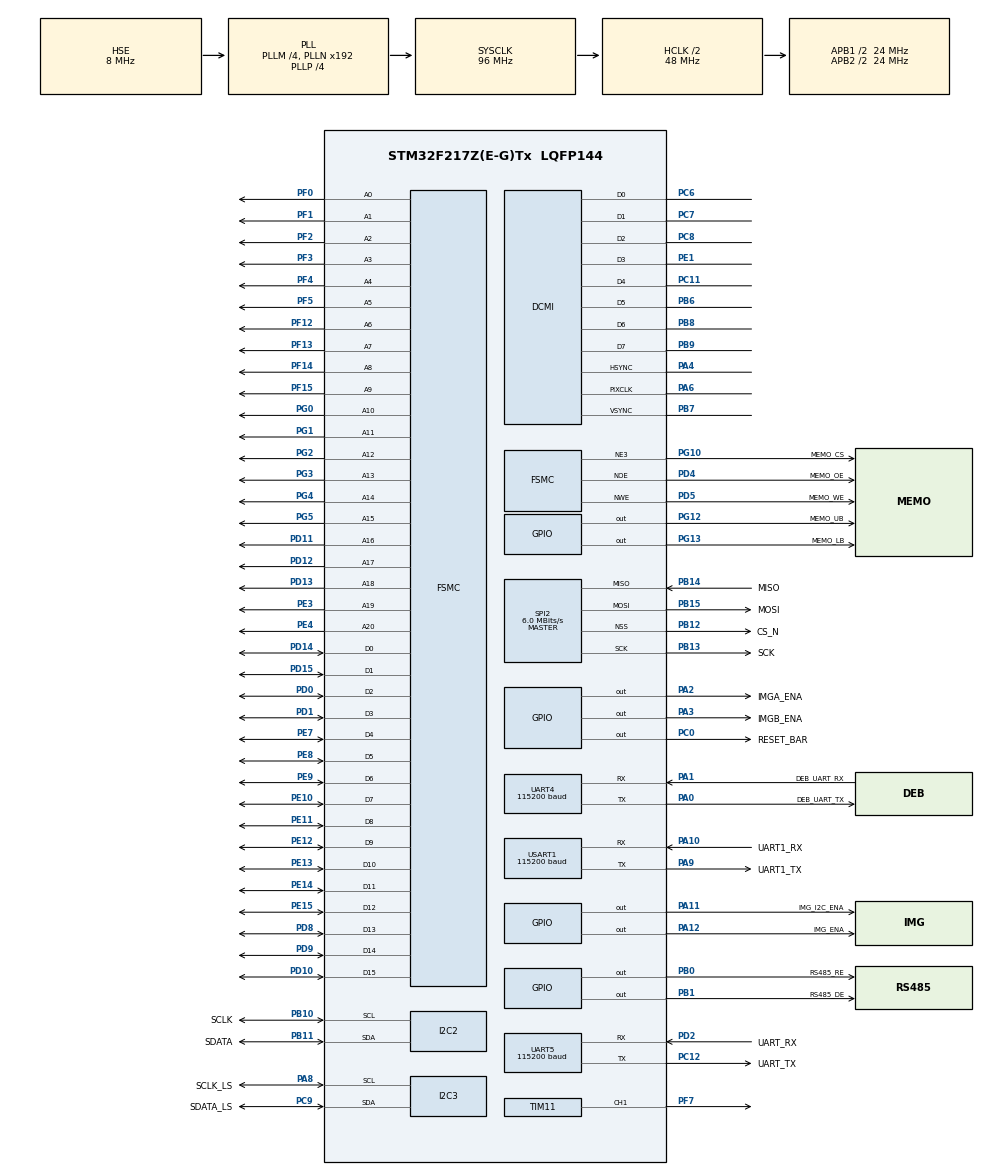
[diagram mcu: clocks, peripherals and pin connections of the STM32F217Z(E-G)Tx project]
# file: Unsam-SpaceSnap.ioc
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DCMI.HSPolarity=DCMI_HSPOLARITY_HIGH
DCMI.JPEGMode=DCMI_JPEG_DISABLE
DCMI.VSPolarity=DCMI_VSPOLARITY_HIGH
FSMC.AddressSetupTime1=2
FSMC.BusTurnAroundDuration1=2
FSMC.DataSetupTime1=2
FSMC.WriteOperation1=FSMC_WRITE_OPERATION_ENABLE
I2C2.AddressingMode=I2C_ADDRESSINGMODE_10BIT
I2C3.OwnAddress=0x7
Mcu.Family=STM32F2
Mcu.Name=STM32F217Z(E-G)Tx
Mcu.Package=LQFP144
NVIC.PriorityGroup=NVIC_PRIORITYGROUP_4
PA0-WKUP.GPIO_Label=DEB_UART_TX
PA0-WKUP.Mode=Asynchronous
PA0-WKUP.Signal=UART4_TX
PA1.GPIO_Label=DEB_UART_RX
PA1.Mode=Asynchronous
PA1.Signal=UART4_RX
PA10.GPIO_Label=UART1_RX
PA10.Mode=Asynchronous
PA10.Signal=USART1_RX
PA11.GPIO_Label=IMG_I2C_ENA
PA11.GPIO_PuPd=GPIO_NOPULL
PA11.Signal=GPIO_Output
PA12.GPIO_Label=IMG_ENA
PA12.Signal=GPIO_Output
PA13.Mode=JTAG_5_pins
PA13.Signal=SYS_JTMS-SWDIO
PA14.Mode=JTAG_5_pins
PA14.Signal=SYS_JTCK-SWCLK
PA15.Mode=JTAG_5_pins
PA15.Signal=SYS_JTDI
PA2.GPIO_Label=IMGA_ENA
PA2.Signal=GPIO_Output
PA3.GPIO_Label=IMGB_ENA
PA3.Signal=GPIO_Output
PA4.Mode=Slave_8_bits_External_Synchro
PA4.Signal=DCMI_HSYNC
PA6.Mode=Slave_8_bits_External_Synchro
PA6.Signal=DCMI_PIXCLK
PA8.GPIO_Label=SCLK_LS
PA8.Mode=I2C
PA8.Signal=I2C3_SCL
PA9.GPIO_Label=UART1_TX
PA9.Mode=Asynchronous
PA9.Signal=USART1_TX
PB0.GPIO_Label=RS485_RE
PB0.Signal=GPIO_Output
PB1.GPIO_Label=RS485_DE
PB1.Signal=GPIO_Output
PB10.GPIO_Label=SCLK
PB10.Mode=I2C
PB10.Signal=I2C2_SCL
PB11.GPIO_Label=SDATA
PB11.Mode=I2C
PB11.Signal=I2C2_SDA
PB12.GPIO_Label=CS_N
PB12.Mode=NSS_Signal_Hard_Output
PB12.Signal=SPI2_NSS
PB13.GPIO_Label=SCK
PB13.Mode=Full_Duplex_Master
PB13.Signal=SPI2_SCK
PB14.GPIO_Label=MISO
PB14.Mode=Full_Duplex_Master
PB14.Signal=SPI2_MISO
PB15.GPIO_Label=MOSI
PB15.Mode=Full_Duplex_Master
PB15.Signal=SPI2_MOSI
PB3.Mode=JTAG_5_pins
PB3.Signal=SYS_JTDO-SWO
PB4.Mode=JTAG_5_pins
PB4.Signal=SYS_JTRST
PB6.Mode=Slave_8_bits_External_Synchro
PB6.Signal=DCMI_D5
PB7.Mode=Slave_8_bits_External_Synchro
PB7.Signal=DCMI_VSYNC
PB8.Mode=Slave_8_bits_External_Synchro
PB8.Signal=DCMI_D6
PB9.Mode=Slave_8_bits_External_Synchro
PB9.Signal=DCMI_D7
PC0.GPIO_Label=RESET_BAR
PC0.Signal=GPIO_Output
PC11.Mode=Slave_8_bits_External_Synchro
PC11.Signal=DCMI_D4
PC12.GPIO_Label=UART_TX
PC12.Mode=Asynchronous
PC12.Signal=UART5_TX
PC14-OSC32_IN.Mode=LSE-External-Oscillator
PC14-OSC32_IN.Signal=RCC_OSC32_IN
PC15-OSC32_OUT.Mode=LSE-External-Oscillator
PC15-OSC32_OUT.Signal=RCC_OSC32_OUT
PC6.Mode=Slave_8_bits_External_Synchro
PC6.Signal=DCMI_D0
PC7.Mode=Slave_8_bits_External_Synchro
PC7.Signal=DCMI_D1
PC8.Mode=Slave_8_bits_External_Synchro
PC8.Signal=DCMI_D2
PC9.GPIO_Label=SDATA_LS
PC9.Mode=I2C
PC9.Signal=I2C3_SDA
PD0.Signal=FSMC_D2_DA2
PD1.Signal=FSMC_D3_DA3
PD10.Signal=FSMC_D15_DA15
PD11.Signal=FSMC_A16_CLE
PD12.Signal=FSMC_A17_ALE
PD13.Signal=FSMC_A18
PD14.Signal=FSMC_D0_DA0
PD15.Signal=FSMC_D1_DA1
PD2.GPIO_Label=UART_RX
PD2.Mode=Asynchronous
PD2.Signal=UART5_RX
PD4.GPIO_Label=MEMO_OE
PD4.Signal=FSMC_NOE
PD5.GPIO_Label=MEMO_WE
PD5.Signal=FSMC_NWE
PD8.Signal=FSMC_D13_DA13
PD9.Signal=FSMC_D14_DA14
PE1.Mode=Slave_8_bits_External_Synchro
PE1.Signal=DCMI_D3
PE10.Signal=FSMC_D7_DA7
PE11.Signal=FSMC_D8_DA8
PE12.Signal=FSMC_D9_DA9
PE13.Signal=FSMC_D10_DA10
PE14.Signal=FSMC_D11_DA11
PE15.Signal=FSMC_D12_DA12
PE3.Signal=FSMC_A19
PE4.Signal=FSMC_A20
PE7.Signal=FSMC_D4_DA4
PE8.Signal=FSMC_D5_DA5
PE9.Signal=FSMC_D6_DA6
PF0.Signal=FSMC_A0
PF1.Signal=FSMC_A1
PF12.Signal=FSMC_A6
PF13.Signal=FSMC_A7
PF14.Signal=FSMC_A8
PF15.Signal=FSMC_A9
PF2.Signal=FSMC_A2
PF3.Signal=FSMC_A3
PF4.Signal=FSMC_A4
PF5.Signal=FSMC_A5
PF7.Signal=S_TIM11_CH1
PG0.Signal=FSMC_A10
PG1.Signal=FSMC_A11
PG10.GPIO_Label=MEMO_CS
PG10.Mode=NorPsramChipSelect3_1
PG10.Signal=FSMC_NE3
PG12.GPIO_Label=MEMO_UB
PG12.GPIO_ModeDefaultOutputPP=GPIO_MODE_OUTPUT_PP
PG12.GPIO_PuPd=GPIO_PULLDOWN
PG12.Signal=GPIO_Output
PG13.GPIO_Label=MEMO_LB
PG13.GPIO_PuPd=GPIO_PULLDOWN
PG13.Signal=GPIO_Output
PG2.Signal=FSMC_A12
PG3.Signal=FSMC_A13
PG4.Signal=FSMC_A14
PG5.Signal=FSMC_A15
PH0-OSC_IN.GPIO_Label=OSC_IN
PH0-OSC_IN.Mode=HSE-External-Oscillator
PH0-OSC_IN.Signal=RCC_OSC_IN
PH1-OSC_OUT.GPIO_Label=OSC_OUT
PH1-OSC_OUT.Mode=HSE-External-Oscillator
PH1-OSC_OUT.Signal=RCC_OSC_OUT
ProjectManager.HeapSize=0x200
ProjectManager.StackSize=0x400
ProjectManager.TargetToolchain=STM32CubeIDE
RCC.48MHZClocksFreq_Value=96000000
RCC.AHBCLKDivider=RCC_SYSCLK_DIV2
RCC.AHBFreq_Value=48000000
RCC.APB1CLKDivider=RCC_HCLK_DIV2
RCC.APB1Freq_Value=24000000
RCC.APB1TimFreq_Value=48000000
RCC.APB2CLKDivider=RCC_HCLK_DIV2
RCC.APB2Freq_Value=24000000
RCC.APB2TimFreq_Value=48000000
RCC.CortexFreq_Value=48000000
RCC.HCLKFreq_Value=48000000
RCC.HSE_VALUE=8000000
RCC.HSI_VALUE=16000000
RCC.PLLM=4
RCC.PLLP=RCC_PLLP_DIV4
RCC.PLLSourceVirtual=RCC_PLLSOURCE_HSE
RCC.SYSCLKFreq_VALUE=96000000
RCC.SYSCLKSource=RCC_SYSCLKSOURCE_PLLCLK
RCC.VCOOutputFreq_Value=384000000
SH.FSMC_A0.0=FSMC_A0,21b-a1
SH.FSMC_A1.0=FSMC_A1,21b-a1
SH.FSMC_A10.0=FSMC_A10,21b-a1
SH.FSMC_A11.0=FSMC_A11,21b-a1
SH.FSMC_A12.0=FSMC_A12,21b-a1
SH.FSMC_A13.0=FSMC_A13,21b-a1
SH.FSMC_A14.0=FSMC_A14,21b-a1
SH.FSMC_A15.0=FSMC_A15,21b-a1
SH.FSMC_A16_CLE.0=FSMC_A16,21b-a1
SH.FSMC_A17_ALE.0=FSMC_A17,21b-a1
SH.FSMC_A18.0=FSMC_A18,21b-a1
SH.FSMC_A19.0=FSMC_A19,21b-a1
SH.FSMC_A2.0=FSMC_A2,21b-a1
SH.FSMC_A20.0=FSMC_A20,21b-a1
SH.FSMC_A3.0=FSMC_A3,21b-a1
SH.FSMC_A4.0=FSMC_A4,21b-a1
SH.FSMC_A5.0=FSMC_A5,21b-a1
SH.FSMC_A6.0=FSMC_A6,21b-a1
SH.FSMC_A7.0=FSMC_A7,21b-a1
SH.FSMC_A8.0=FSMC_A8,21b-a1
SH.FSMC_A9.0=FSMC_A9,21b-a1
SH.FSMC_D0_DA0.0=FSMC_D0,16b-d1
SH.FSMC_D10_DA10.0=FSMC_D10,16b-d1
SH.FSMC_D11_DA11.0=FSMC_D11,16b-d1
SH.FSMC_D12_DA12.0=FSMC_D12,16b-d1
SH.FSMC_D13_DA13.0=FSMC_D13,16b-d1
SH.FSMC_D14_DA14.0=FSMC_D14,16b-d1
SH.FSMC_D15_DA15.0=FSMC_D15,16b-d1
SH.FSMC_D1_DA1.0=FSMC_D1,16b-d1
SH.FSMC_D2_DA2.0=FSMC_D2,16b-d1
SH.FSMC_D3_DA3.0=FSMC_D3,16b-d1
SH.FSMC_D4_DA4.0=FSMC_D4,16b-d1
SH.FSMC_D5_DA5.0=FSMC_D5,16b-d1
SH.FSMC_D6_DA6.0=FSMC_D6,16b-d1
SH.FSMC_D7_DA7.0=FSMC_D7,16b-d1
SH.FSMC_D8_DA8.0=FSMC_D8,16b-d1
SH.FSMC_D9_DA9.0=FSMC_D9,16b-d1
SH.FSMC_NOE.0=FSMC_NOE,Sram1
SH.FSMC_NWE.0=FSMC_NWE,Sram1
SH.S_TIM11_CH1.0=TIM11_CH1,PWM Generation1 CH1
SPI2.BaudRatePrescaler=SPI_BAUDRATEPRESCALER_4
SPI2.CalculateBaudRate=6.0 MBits/s
SPI2.Direction=SPI_DIRECTION_2LINES
SPI2.Mode=SPI_MODE_MASTER
SPI2.TIMode=SPI_TIMODE_ENABLE
SPI2.VirtualNSS=VM_NSSHARD
SPI2.VirtualType=VM_MASTER
TIM11.Channel=TIM_CHANNEL_1
TIM11.Period=1
TIM11.Prescaler=2
UART4.BaudRate=115200
UART4.VirtualMode=Asynchronous
UART5.BaudRate=115200
UART5.VirtualMode=Asynchronous
USART1.BaudRate=115200
USART1.VirtualMode=VM_ASYNC
VP_TIM11_VS_ClockSourceINT.Mode=Enable_Timer
board=custom

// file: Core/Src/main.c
/* USER CODE BEGIN Header */
/**
  ******************************************************************************
  * @file           : main.c
  * @brief          : Main program body
  ******************************************************************************
  * @attention
  *
  * Copyright (c) 2025 STMicroelectronics.
  * All rights reserved.
  *
  * This software is licensed under terms that can be found in the LICENSE file
  * in the root directory of this software component.
  * If no LICENSE file comes with this software, it is provided AS-IS.
  *
  ******************************************************************************
  */
/* USER CODE END Header */
#include "main.h"
#include "dcmi.h"
#include "i2c.h"
#include "spi.h"
#include "tim.h"
#include "usart.h"
#include "gpio.h"
#include "fsmc.h"
#include "photo.h"
#include "fram.h"

#include <stdio.h>

/* USER CODE BEGIN PM */

#define COMM_UART	// defines communication with LS-02 as UART
//#define COMM_I2C	// defines communication with LS-02 as i2C

#define USE_FULL_ASSERT

/* USER CODE END PM */

/* USER CODE BEGIN PV */

typedef enum {								// State machine for program flow
    STATE_IDLE = 0,
    STATE_EXECUTE_COMMAND,
	STATE_TRANSMIT_RESPONSE
} app_state_t;

uint32_t timestamp;
char *timestamp_string;
char *log_message; 							// placeholder for log messages
status_t *mission_status;

volatile raw_photo_t* raw_buffer_1;
volatile raw_photo_t* raw_buffer_2;
volatile raw_photo_t* raw_buffer_3;
volatile raw_photo_t* raw_buffers[NUM_BUFFERS];

// Metadata for compressed photo buffer
volatile compressed_metadata_t* compressed_metadata[MAX_COMPRESSED_PICS];
uint16_t* compressed_photo_space;		// TODO - Check how we can initialize this memory statically. Program might crash if not done.
uint16_t* current_compressed_address;
uint8_t current_compressed_index;

uint8_t* compressed_photo_space_FRAM;
uint8_t* current_compressed_address_FRAM;
uint8_t current_compressed_index_FRAM;

// global camera registers to write and their parameters
volatile uint8_t camera_regs_A[20];
volatile uint8_t camera_regs_B[20];
volatile uint8_t camera_params_A[20];
volatile uint8_t camera_params_B[20];

// timestamp saved in FRAM
volatile uint32_t ts_fram;

// Total photos taken
volatile uint16_t photos_taken;

// Total frames sent
volatile uint32_t total_frames_sent;

// Total time on
volatile uint32_t time_on;

/* USER CODE END PV */

void SystemClock_Config(void);

int main(void)
{

  /* MCU Configuration--------------------------------------------------------*/

  /* Reset of all peripherals, Initializes the Flash interface and the Systick. */
  HAL_Init();

  /* USER CODE BEGIN Init */

  app_state_t state = STATE_IDLE;							// program starts in IDLE state
  uint8_t current_instruction;								// current program instruction
  const command_t* current_command_pointer;					// pointer to current command
  uint8_t rx_buffer_copy[INSTRUCTION_SIZE];					// copy of rx buffer in program memory
  HAL_StatusTypeDef ret = 0;								// return for ExecuteCommand()

  Init_status(mission_status);					// loads status from FRAM memory

  photos_taken = mission_status->photos_taken;
  ts_fram = mission_status->time_on;
  total_frames_sent = mission_status->total_frames_sent;		// TODO - code to update status in FRAM

  MX_FSMC_Init();											// initializes external SRAM
  MX_DCMI_Init();											// Initializes DCMI

  /* USER CODE END Init */

  /* Configure the system clock */
  SystemClock_Config();

  /* USER CODE BEGIN SysInit */

  init_camera_buffers();		// Allocates memory for raw photo buffers

  // FRAM initialization
  FRAM_InitDelay();
  HAL_GPIO_WritePin(GPIOB, GPIO_PIN_12, GPIO_PIN_SET); 	// ensure CS high

  // TODO - Load contents of FRAM to SRAM (backup in case of power down)
  timestamp = ts_fram + HAL_GetTick(); 	// system timestamp in 1ms intervals - Updated by interrupt

  /* USER CODE END SysInit */

  /* Initialize all configured peripherals */
  MX_GPIO_Init();
  MX_I2C3_Init();
  MX_USART1_UART_Init();
  MX_DCMI_Init();
  MX_FSMC_Init();
  MX_I2C2_Init();
  MX_SPI2_Init();
  MX_TIM11_Init();
  MX_UART4_Init();
  MX_UART5_Init();
  /* USER CODE BEGIN 2 */

  #if defined(COMM_UART) && !defined(COMM_I2C)
  	  HAL_UART_Receive_IT(&huart1, (uint8_t*)rx_buffer, INSTRUCTION_SIZE);
  #elif defined(COMM_I2C) && !defined(COMM_UART)
  	  HAL_I2C_Slave_Receive_IT(&hi2c3, (uint8_t *)rx_buffer, INSTRUCTION_SIZE);
  #else
  	  #warning "Invalid configuration detected in USS <--> LS-02 communication.\n"
  #endif

  /* USER CODE END 2 */

  /* Infinite loop */
  /* USER CODE BEGIN WHILE */
  while (1)
  {
	  switch (state) {
		  case STATE_IDLE:
			  if (new_command_received) {
				  new_command_received = 0;
				  state = STATE_EXECUTE_COMMAND;
			  }
			  break;

		  case STATE_EXECUTE_COMMAND:
			  CopyVolatile(rx_buffer_copy, rx_buffer);														// copies rx_buffer into non-volatile
			  current_instruction = rx_buffer_copy[0];
			  current_command_pointer = GetCommand(current_instruction);

			  ret = ExecuteCommand(current_command_pointer, &rx_buffer_copy[1]);
			  if (ret == HAL_OK) Log("Return success\n");
			  else Log("Return failure!\n");

			  state = STATE_TRANSMIT_RESPONSE;
			  break;

		  case STATE_TRANSMIT_RESPONSE:
			  #if defined(COMM_UART) && !defined(COMM_I2C)
				  TransmitBufferUART();
			  #elif defined(COMM_I2C) && !defined(COMM_UART)
				  TransmitBufferi2C();
			  #endif
			  state = STATE_IDLE;
			  break;

		  default:
			  state = STATE_IDLE;
			  break;
	  }

    /* USER CODE END WHILE */

  }
}

void SystemClock_Config(void)
{
  RCC_OscInitTypeDef RCC_OscInitStruct = {0};
  RCC_ClkInitTypeDef RCC_ClkInitStruct = {0};

  /** Initializes the RCC Oscillators according to the specified parameters
  * in the RCC_OscInitTypeDef structure.
  */
  RCC_OscInitStruct.OscillatorType = RCC_OSCILLATORTYPE_HSE;
  RCC_OscInitStruct.HSEState = RCC_HSE_ON;
  RCC_OscInitStruct.PLL.PLLState = RCC_PLL_ON;
  RCC_OscInitStruct.PLL.PLLSource = RCC_PLLSOURCE_HSE;
  RCC_OscInitStruct.PLL.PLLM = 4;
  RCC_OscInitStruct.PLL.PLLN = 192;
  RCC_OscInitStruct.PLL.PLLP = RCC_PLLP_DIV4;
  RCC_OscInitStruct.PLL.PLLQ = 4;
  if (HAL_RCC_OscConfig(&RCC_OscInitStruct) != HAL_OK)
  {
    Error_Handler();
  }

  /** Initializes the CPU, AHB and APB buses clocks
  */
  RCC_ClkInitStruct.ClockType = RCC_CLOCKTYPE_HCLK|RCC_CLOCKTYPE_SYSCLK
                              |RCC_CLOCKTYPE_PCLK1|RCC_CLOCKTYPE_PCLK2;
  RCC_ClkInitStruct.SYSCLKSource = RCC_SYSCLKSOURCE_PLLCLK;
  RCC_ClkInitStruct.AHBCLKDivider = RCC_SYSCLK_DIV2;
  RCC_ClkInitStruct.APB1CLKDivider = RCC_HCLK_DIV2;
  RCC_ClkInitStruct.APB2CLKDivider = RCC_HCLK_DIV2;

  if (HAL_RCC_ClockConfig(&RCC_ClkInitStruct, FLASH_LATENCY_1) != HAL_OK)
  {
    Error_Handler();
  }
}

void Error_Handler(void)
{
	__disable_irq();
	while (1)
	{
	}
}

#ifdef  USE_FULL_ASSERT
/**
  * @brief  Reports the name of the source file and the source line number
  *         where the assert_param error has occurred.
  * @param  file: pointer to the source file name
  * @param  line: assert_param error line source number
  * @retval None
  */
void assert_failed(uint8_t *file, uint32_t line)
{
  /* USER CODE BEGIN 6 */
  /* User can add his own implementation to report the file name and line number,
     ex: printf("Wrong parameters value: file %s on line %d\r\n", file, line) */

	perror("kp");

  /* USER CODE END 6 */
}
#endif /* USE_FULL_ASSERT */
